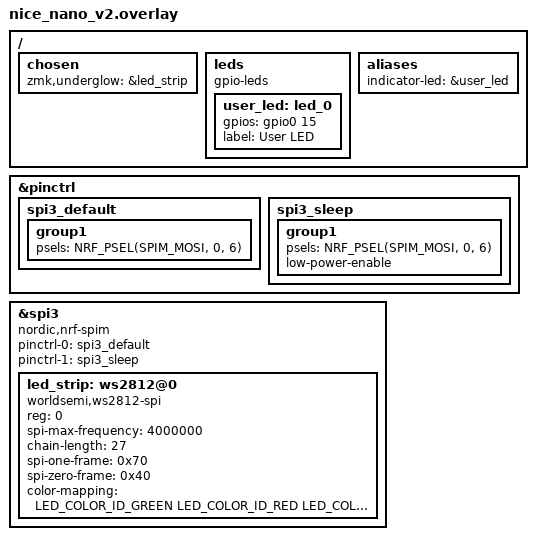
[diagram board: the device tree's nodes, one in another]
/*
 * RGB (2 LEDs por switch: uno arriba, uno abajo) para nice_nano_v2 en el
 * shield corne.
 *
 * Pin: P0.06 (SPI3 MOSI). No confirmado oficialmente por el vendedor
 * (Typeractive no documenta RGB para este PCB); se infirio de:
 *   - app/boards/shields/corne/boards/nice_nano.overlay en zmkfirmware/zmk
 *     (mismo pin, mismo patron SPI, para nice_nano v1).
 *   - La lista de "pines libres" del pinout oficial de Typeractive para
 *     este PCB (docs.typeractive.xyz/build-guides/corne-wireless/troubleshooting),
 *     donde P0.06 aparece como no usado por la matriz ni el nice!view.
 * Confirmado funcional: con este pin los LEDs encienden y responden al
 * efecto configurado.
 *
 * chain-length: 27 LEDs por mitad (6 underglow + 21 per-key, confirmado por
 * conteo fisico). ESTADO ACEPTADO: solo encienden 10 de 27 (los 6
 * underglow + los primeros ~4 per-key). Se investigo a fondo (hardware
 * confirmado bien con QMK, sin errores de software en el log USB,
 * frecuencia SPI probada en 2/4/8MHz sin cambios) sin encontrar la causa
 * exacta - probablemente un problema de señal a nivel electrico fuera del
 * alcance de config/devicetree. Ver README.md para el detalle completo y
 * las alternativas evaluadas (driver GPIO custom, I2S, Discord de ZMK).
 */

#include <dt-bindings/led/led.h>
#include <zephyr/dt-bindings/gpio/gpio.h>

&pinctrl {
    spi3_default: spi3_default {
        group1 {
            psels = <NRF_PSEL(SPIM_MOSI, 0, 6)>;
        };
    };

    spi3_sleep: spi3_sleep {
        group1 {
            psels = <NRF_PSEL(SPIM_MOSI, 0, 6)>;
            low-power-enable;
        };
    };
};

&spi3 {
    compatible = "nordic,nrf-spim";
    status = "okay";

    pinctrl-0 = <&spi3_default>;
    pinctrl-1 = <&spi3_sleep>;
    pinctrl-names = "default", "sleep";

    led_strip: ws2812@0 {
        compatible = "worldsemi,ws2812-spi";

        /* SPI */
        reg = <0>; /* ignorado, pero necesario para el binding SPI */
        /* Se probaron 2MHz, 4MHz y 8MHz para el problema de LEDs que no
         * encienden pasado el #10 de 27 (ver README.md) - resultado
         * identico en los 3, la frecuencia SPI no es la causa. Vuelto al
         * valor de referencia original de ZMK (4MHz). */
        spi-max-frequency = <4000000>;

        /* WS2812 / SK6812 */
        chain-length = <27>; /* 6 underglow + 21 per-key */
        spi-one-frame = <0x70>;
        spi-zero-frame = <0x40>;

        color-mapping = <LED_COLOR_ID_GREEN LED_COLOR_ID_RED LED_COLOR_ID_BLUE>;
    };
};

/*
 * LED azul integrado del nice!nano (indicador de bateria via
 * zmk-poor-mans-led-indicator). Pin P0.15, confirmado de forma
 * independiente por la documentacion de TinyGo para nice!nano y por el
 * ejemplo del propio modulo. Separado por completo de la cadena RGB de
 * arriba (led_strip en P0.06) - funciona aunque el RGB este apagado.
 */
/ {
    chosen {
        zmk,underglow = &led_strip;
    };

    leds {
        compatible = "gpio-leds";
        user_led: led_0 {
            gpios = <&gpio0 15 GPIO_ACTIVE_HIGH>;
            label = "User LED";
        };
    };

    aliases {
        indicator-led = &user_led;
    };
};
